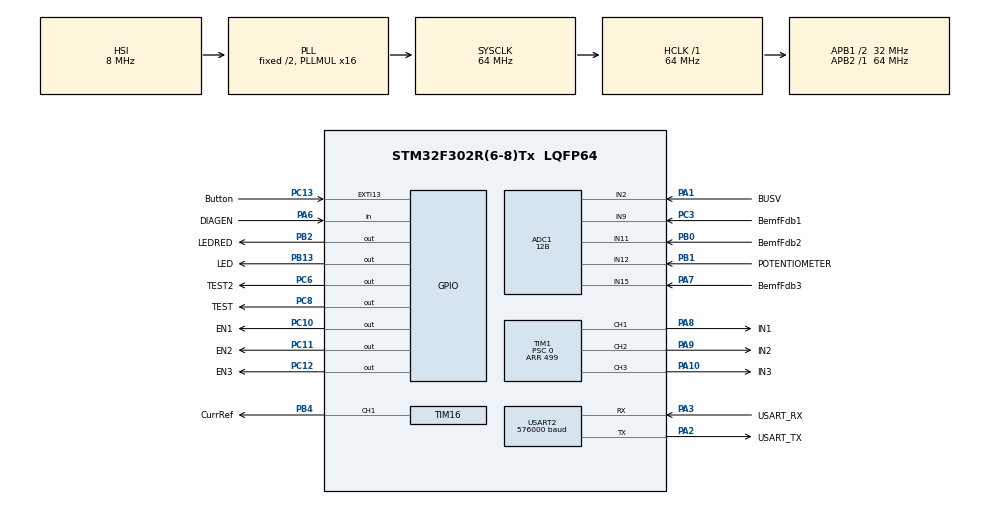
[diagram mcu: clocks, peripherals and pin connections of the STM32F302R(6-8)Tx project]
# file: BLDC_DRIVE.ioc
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ADC1.Channel-55\#ChannelRegularConversion=ADC_CHANNEL_12
ADC1.Channel-56\#ChannelRegularConversion=ADC_CHANNEL_9
ADC1.Channel-57\#ChannelRegularConversion=ADC_CHANNEL_11
ADC1.Channel-58\#ChannelRegularConversion=ADC_CHANNEL_9
ADC1.Channel-59\#ChannelRegularConversion=ADC_CHANNEL_9
ADC1.Channel-60\#ChannelRegularConversion=ADC_CHANNEL_2
ADC1.Channel-61\#ChannelRegularConversion=ADC_CHANNEL_2
ADC1.Channel-62\#ChannelRegularConversion=ADC_CHANNEL_2
ADC1.Channel-63\#ChannelRegularConversion=ADC_CHANNEL_2
ADC1.Channel-64\#ChannelRegularConversion=ADC_CHANNEL_2
ADC1.Channel-65\#ChannelRegularConversion=ADC_CHANNEL_2
ADC1.Channel-66\#ChannelRegularConversion=ADC_CHANNEL_9
ADC1.Channel-67\#ChannelRegularConversion=ADC_CHANNEL_11
ADC1.Channel-68\#ChannelRegularConversion=ADC_CHANNEL_15
ADC1.Channel-69\#ChannelRegularConversion=ADC_CHANNEL_9
ADC1.Channel-70\#ChannelRegularConversion=ADC_CHANNEL_11
ADC1.Channel-71\#ChannelRegularConversion=ADC_CHANNEL_15
ADC1.Channel-72\#ChannelRegularConversion=ADC_CHANNEL_9
ADC1.Channel-73\#ChannelRegularConversion=ADC_CHANNEL_11
ADC1.Channel-74\#ChannelRegularConversion=ADC_CHANNEL_15
ADC1.Channel-76\#ChannelRegularConversion=ADC_CHANNEL_12
ADC1.ClockPrescaler=ADC_CLOCK_SYNC_PCLK_DIV1
ADC1.ContinuousConvMode=DISABLE
ADC1.DMAContinuousRequests=ENABLE
ADC1.DataAlign=ADC_DATAALIGN_RIGHT
ADC1.DiscontinuousConvMode=DISABLE
ADC1.EOCSelection=ADC_EOC_SINGLE_CONV
ADC1.EnableAnalogWatchDog1=false
ADC1.EnableAnalogWatchDog2=false
ADC1.EnableAnalogWatchDog3=false
ADC1.EnableInjectedConversion=DISABLE
ADC1.EnableRegularConversion=ENABLE
ADC1.ExternalTrigConv=ADC_EXTERNALTRIGCONV_T1_TRGO
ADC1.ExternalTrigConvEdge=ADC_EXTERNALTRIGCONVEDGE_RISING
ADC1.LowPowerAutoWait=DISABLE
ADC1.NbrOfConversion=10
ADC1.NbrOfConversionFlag=1
ADC1.Offset-55\#ChannelRegularConversion=0
ADC1.Offset-56\#ChannelRegularConversion=0
ADC1.Offset-57\#ChannelRegularConversion=0
ADC1.Offset-58\#ChannelRegularConversion=0
ADC1.Offset-59\#ChannelRegularConversion=0
ADC1.Offset-60\#ChannelRegularConversion=0
ADC1.Offset-61\#ChannelRegularConversion=0
ADC1.Offset-62\#ChannelRegularConversion=0
ADC1.Offset-63\#ChannelRegularConversion=0
ADC1.Offset-64\#ChannelRegularConversion=0
ADC1.Offset-65\#ChannelRegularConversion=0
ADC1.Offset-66\#ChannelRegularConversion=0
ADC1.Offset-67\#ChannelRegularConversion=0
ADC1.Offset-68\#ChannelRegularConversion=0
ADC1.Offset-69\#ChannelRegularConversion=0
ADC1.Offset-70\#ChannelRegularConversion=0
ADC1.Offset-71\#ChannelRegularConversion=0
ADC1.Offset-72\#ChannelRegularConversion=0
ADC1.Offset-73\#ChannelRegularConversion=0
ADC1.Offset-74\#ChannelRegularConversion=0
ADC1.Offset-76\#ChannelRegularConversion=0
ADC1.OffsetNumber-55\#ChannelRegularConversion=ADC_OFFSET_NONE
ADC1.OffsetNumber-56\#ChannelRegularConversion=ADC_OFFSET_NONE
ADC1.OffsetNumber-57\#ChannelRegularConversion=ADC_OFFSET_NONE
ADC1.OffsetNumber-58\#ChannelRegularConversion=ADC_OFFSET_NONE
ADC1.OffsetNumber-59\#ChannelRegularConversion=ADC_OFFSET_NONE
ADC1.OffsetNumber-60\#ChannelRegularConversion=ADC_OFFSET_NONE
ADC1.OffsetNumber-61\#ChannelRegularConversion=ADC_OFFSET_NONE
ADC1.OffsetNumber-62\#ChannelRegularConversion=ADC_OFFSET_NONE
ADC1.OffsetNumber-63\#ChannelRegularConversion=ADC_OFFSET_NONE
ADC1.OffsetNumber-64\#ChannelRegularConversion=ADC_OFFSET_NONE
ADC1.OffsetNumber-65\#ChannelRegularConversion=ADC_OFFSET_NONE
ADC1.OffsetNumber-66\#ChannelRegularConversion=ADC_OFFSET_NONE
ADC1.OffsetNumber-67\#ChannelRegularConversion=ADC_OFFSET_NONE
ADC1.OffsetNumber-68\#ChannelRegularConversion=ADC_OFFSET_NONE
ADC1.OffsetNumber-69\#ChannelRegularConversion=ADC_OFFSET_NONE
ADC1.OffsetNumber-70\#ChannelRegularConversion=ADC_OFFSET_NONE
ADC1.OffsetNumber-71\#ChannelRegularConversion=ADC_OFFSET_NONE
ADC1.OffsetNumber-72\#ChannelRegularConversion=ADC_OFFSET_NONE
ADC1.OffsetNumber-73\#ChannelRegularConversion=ADC_OFFSET_NONE
ADC1.OffsetNumber-74\#ChannelRegularConversion=ADC_OFFSET_NONE
ADC1.OffsetNumber-76\#ChannelRegularConversion=ADC_OFFSET_NONE
ADC1.Overrun=ADC_OVR_DATA_OVERWRITTEN
ADC1.Rank-55\#ChannelRegularConversion=1
ADC1.Rank-56\#ChannelRegularConversion=2
ADC1.Rank-57\#ChannelRegularConversion=3
ADC1.Rank-58\#ChannelRegularConversion=4
ADC1.Rank-59\#ChannelRegularConversion=5
ADC1.Rank-60\#ChannelRegularConversion=6
ADC1.Rank-61\#ChannelRegularConversion=7
ADC1.Rank-62\#ChannelRegularConversion=8
ADC1.Rank-63\#ChannelRegularConversion=9
ADC1.Rank-64\#ChannelRegularConversion=10
ADC1.Rank-65\#ChannelRegularConversion=1
ADC1.Rank-66\#ChannelRegularConversion=1
ADC1.Rank-67\#ChannelRegularConversion=2
ADC1.Rank-68\#ChannelRegularConversion=3
ADC1.Rank-69\#ChannelRegularConversion=4
ADC1.Rank-70\#ChannelRegularConversion=5
ADC1.Rank-71\#ChannelRegularConversion=6
ADC1.Rank-72\#ChannelRegularConversion=7
ADC1.Rank-73\#ChannelRegularConversion=8
ADC1.Rank-74\#ChannelRegularConversion=9
ADC1.Rank-76\#ChannelRegularConversion=10
ADC1.Resolution=ADC_RESOLUTION_12B
ADC1.SamplingTime-55\#ChannelRegularConversion=ADC_SAMPLETIME_61CYCLES_5
ADC1.SamplingTime-56\#ChannelRegularConversion=ADC_SAMPLETIME_1CYCLE_5
ADC1.SamplingTime-57\#ChannelRegularConversion=ADC_SAMPLETIME_1CYCLE_5
ADC1.SamplingTime-58\#ChannelRegularConversion=ADC_SAMPLETIME_1CYCLE_5
ADC1.SamplingTime-59\#ChannelRegularConversion=ADC_SAMPLETIME_1CYCLE_5
ADC1.SamplingTime-60\#ChannelRegularConversion=ADC_SAMPLETIME_1CYCLE_5
ADC1.SamplingTime-61\#ChannelRegularConversion=ADC_SAMPLETIME_1CYCLE_5
ADC1.SamplingTime-62\#ChannelRegularConversion=ADC_SAMPLETIME_1CYCLE_5
ADC1.SamplingTime-63\#ChannelRegularConversion=ADC_SAMPLETIME_1CYCLE_5
ADC1.SamplingTime-64\#ChannelRegularConversion=ADC_SAMPLETIME_1CYCLE_5
ADC1.SamplingTime-65\#ChannelRegularConversion=ADC_SAMPLETIME_1CYCLE_5
ADC1.SamplingTime-66\#ChannelRegularConversion=ADC_SAMPLETIME_61CYCLES_5
ADC1.SamplingTime-67\#ChannelRegularConversion=ADC_SAMPLETIME_1CYCLE_5
ADC1.SamplingTime-68\#ChannelRegularConversion=ADC_SAMPLETIME_1CYCLE_5
ADC1.SamplingTime-69\#ChannelRegularConversion=ADC_SAMPLETIME_1CYCLE_5
ADC1.SamplingTime-70\#ChannelRegularConversion=ADC_SAMPLETIME_1CYCLE_5
ADC1.SamplingTime-71\#ChannelRegularConversion=ADC_SAMPLETIME_1CYCLE_5
ADC1.SamplingTime-72\#ChannelRegularConversion=ADC_SAMPLETIME_1CYCLE_5
ADC1.SamplingTime-73\#ChannelRegularConversion=ADC_SAMPLETIME_1CYCLE_5
ADC1.SamplingTime-74\#ChannelRegularConversion=ADC_SAMPLETIME_1CYCLE_5
ADC1.SamplingTime-76\#ChannelRegularConversion=ADC_SAMPLETIME_1CYCLE_5
ADC1.ScanConvMode=ADC_SCAN_ENABLE
ADC1.SubFamily=STM32F302x8
ADC1.master=1
Dma.ADC1.2.Direction=DMA_PERIPH_TO_MEMORY
Dma.ADC1.2.Instance=DMA1_Channel1
Dma.ADC1.2.MemDataAlignment=DMA_MDATAALIGN_HALFWORD
Dma.ADC1.2.MemInc=DMA_MINC_ENABLE
Dma.ADC1.2.Mode=DMA_CIRCULAR
Dma.ADC1.2.PeriphDataAlignment=DMA_PDATAALIGN_HALFWORD
Dma.ADC1.2.PeriphInc=DMA_PINC_DISABLE
Dma.ADC1.2.Priority=DMA_PRIORITY_LOW
Dma.Request0=USART2_TX
Dma.Request1=USART2_RX
Dma.Request2=ADC1
Dma.USART2_RX.1.Direction=DMA_PERIPH_TO_MEMORY
Dma.USART2_RX.1.Instance=DMA1_Channel6
Dma.USART2_RX.1.MemDataAlignment=DMA_MDATAALIGN_BYTE
Dma.USART2_RX.1.MemInc=DMA_MINC_ENABLE
Dma.USART2_RX.1.Mode=DMA_NORMAL
Dma.USART2_RX.1.PeriphDataAlignment=DMA_PDATAALIGN_BYTE
Dma.USART2_RX.1.PeriphInc=DMA_PINC_DISABLE
Dma.USART2_RX.1.Priority=DMA_PRIORITY_LOW
Dma.USART2_TX.0.Direction=DMA_MEMORY_TO_PERIPH
Dma.USART2_TX.0.Instance=DMA1_Channel7
Dma.USART2_TX.0.MemDataAlignment=DMA_MDATAALIGN_BYTE
Dma.USART2_TX.0.MemInc=DMA_MINC_ENABLE
Dma.USART2_TX.0.Mode=DMA_NORMAL
Dma.USART2_TX.0.PeriphDataAlignment=DMA_PDATAALIGN_BYTE
Dma.USART2_TX.0.PeriphInc=DMA_PINC_DISABLE
Dma.USART2_TX.0.Priority=DMA_PRIORITY_LOW
Mcu.Family=STM32F3
Mcu.Name=STM32F302R(6-8)Tx
Mcu.Package=LQFP64
NVIC.ADC1_IRQn=true\:0\:0\:false\:false\:true
NVIC.DMA1_Channel1_IRQn=true\:0\:0\:false\:false\:true
NVIC.DMA1_Channel6_IRQn=true\:0\:0\:false\:false\:true
NVIC.DMA1_Channel7_IRQn=true\:0\:0\:true\:false\:true
NVIC.EXTI15_10_IRQn=true\:0\:0\:false\:false\:true
NVIC.PriorityGroup=NVIC_PRIORITYGROUP_2
NVIC.TIM1_BRK_TIM15_IRQn=true\:0\:0\:false\:false\:true
NVIC.TIM2_IRQn=true\:1\:0\:true\:false\:true
NVIC.USART2_IRQn=true\:3\:0\:true\:false\:true
PA0.GPIO_Label=CurrFdbA
PA0.Signal=ADC1_IN1
PA1.GPIO_Label=BUSV
PA1.Mode=IN2-Single-Ended
PA1.Signal=ADC1_IN2
PA10.GPIO_Label=IN3
PA10.GPIO_Speed=GPIO_SPEED_FREQ_LOW
PA10.Signal=S_TIM1_CH3
PA12.Signal=S_TIM1_ETR
PA13.GPIO_Label=TMS
PA13.Signal=SYS_JTMS-SWDIO
PA14.GPIO_Label=TCK
PA14.Signal=SYS_JTCK-SWCLK
PA2.GPIO_Label=USART_TX
PA2.GPIO_Mode=GPIO_MODE_AF_PP
PA2.GPIO_PuPd=GPIO_NOPULL
PA2.GPIO_Speed=GPIO_SPEED_FREQ_LOW
PA2.Mode=Asynchronous
PA2.Signal=USART2_TX
PA3.GPIO_Label=USART_RX
PA3.GPIO_Mode=GPIO_MODE_AF_PP
PA3.GPIO_PuPd=GPIO_NOPULL
PA3.GPIO_Speed=GPIO_SPEED_FREQ_LOW
PA3.Mode=Asynchronous
PA3.Signal=USART2_RX
PA6.GPIO_Label=DIAGEN
PA6.Signal=GPIO_Input
PA7.GPIO_Label=BemfFdb3
PA7.Mode=IN15-Single-Ended
PA7.Signal=ADC1_IN15
PA8.GPIO_Label=IN1
PA8.GPIO_Speed=GPIO_SPEED_FREQ_LOW
PA8.Signal=S_TIM1_CH1
PA9.GPIO_Label=IN2
PA9.GPIO_Speed=GPIO_SPEED_FREQ_LOW
PA9.Signal=S_TIM1_CH2
PB0.GPIO_Label=BemfFdb2
PB0.Mode=IN11-Single-Ended
PB0.Signal=ADC1_IN11
PB1.GPIO_Label=POTENTIOMETER
PB1.Mode=IN12-Single-Ended
PB1.Signal=ADC1_IN12
PB13.GPIO_Label=LED
PB13.Signal=GPIO_Output
PB2.GPIO_Label=LEDRED
PB2.Signal=GPIO_Output
PB3.GPIO_Label=SWO
PB3.Signal=SYS_JTDO-TRACESWO
PB4.GPIO_Label=CurrRef
PB4.Signal=S_TIM16_CH1
PC0.GPIO_Label=CurrFdbC
PC0.Signal=ADCx_IN6
PC1.GPIO_Label=CurrFdbB
PC1.Signal=ADCx_IN7
PC10.GPIO_Label=EN1
PC10.Signal=GPIO_Output
PC11.GPIO_Label=EN2
PC11.Signal=GPIO_Output
PC12.GPIO_Label=EN3
PC12.Signal=GPIO_Output
PC13.GPIO_Label=Button
PC13.GPIO_ModeDefaultEXTI=GPIO_MODE_IT_FALLING
PC13.Signal=GPXTI13
PC14\ -\ OSC32_IN.Signal=RCC_OSC32_IN
PC15\ -\ OSC32_OUT.Signal=RCC_OSC32_OUT
PC3.GPIO_Label=BemfFdb1
PC3.Signal=ADCx_IN9
PC6.GPIO_Label=TEST2
PC6.Signal=GPIO_Output
PC8.GPIO_Label=TEST
PC8.GPIO_Speed=GPIO_SPEED_FREQ_MEDIUM
PC8.Signal=GPIO_Output
PF0-OSC_IN.Signal=RCC_OSC_IN
PF1-OSC_OUT.Signal=RCC_OSC_OUT
ProjectManager.HeapSize=0x200
ProjectManager.StackSize=0x400
ProjectManager.TargetToolchain=SW4STM32
RCC.AHBFreq_Value=64000000
RCC.APB1CLKDivider=RCC_HCLK_DIV2
RCC.APB1Freq_Value=32000000
RCC.APB1TimFreq_Value=64000000
RCC.APB2Freq_Value=64000000
RCC.APB2TimFreq_Value=64000000
RCC.CortexFreq_Value=64000000
RCC.HCLKFreq_Value=64000000
RCC.HSE_VALUE=8000000
RCC.HSI_VALUE=8000000
RCC.LSE_VALUE=32768
RCC.PLLM=8
RCC.PLLMUL=RCC_PLL_MUL16
RCC.PLLN=336
RCC.PLLP=RCC_PLLP_DIV4
RCC.PLLQ=7
RCC.RCC_PLLsource_Clock_Source_FROM_HSE=RCC_HSE_PREDIV_DIV2
RCC.SYSCLKFreq_VALUE=64000000
RCC.SYSCLKSourceVirtual=RCC_SYSCLKSOURCE_PLLCLK
RCC.USBFreq_Value=64000000
SH.ADCx_IN6.0=ADC1_IN6
SH.ADCx_IN7.0=ADC1_IN7
SH.ADCx_IN9.0=ADC1_IN9,IN9-Single-Ended
SH.S_TIM16_CH1.0=TIM16_CH1,PWM Generation1 CH1
SH.S_TIM1_CH1.0=TIM1_CH1,PWM Generation1 CH1
SH.S_TIM1_CH2.0=TIM1_CH2,PWM Generation2 CH2
SH.S_TIM1_CH3.0=TIM1_CH3,PWM Generation3 CH3
SH.S_TIM1_ETR.0=TIM1_ETR
TIM1.Channel-Output\ Compare4\ No\ Output=TIM_CHANNEL_4
TIM1.Channel-PWM\ Generation2\ CH2=TIM_CHANNEL_2
TIM1.Channel-PWM\ Generation3\ CH3=TIM_CHANNEL_3
TIM1.ClearChannel2=TIM_CHANNEL_2
TIM1.ClearChannel3=TIM_CHANNEL_3
TIM1.CounterMode=TIM_COUNTERMODE_CENTERALIGNED1
TIM1.OCMode_4=TIM_OCMODE_TOGGLE
TIM1.OCMode_PWM-PWM\ Generation1\ CH1=TIM_OCMODE_PWM1
TIM1.OCMode_PWM-PWM\ Generation3\ CH3=TIM_OCMODE_PWM1
TIM1.Period=499
TIM1.Prescaler=0
TIM1.Pulse-Output\ Compare4\ No\ Output=499
TIM1.Pulse-PWM\ Generation1\ CH1=0
TIM1.Pulse-PWM\ Generation2\ CH2=0
TIM1.Pulse-PWM\ Generation3\ CH3=0
TIM1.TIM_MasterOutputTrigger=TIM_TRGO_OC4REF
TIM15.Period=1129
TIM15.Prescaler=9999
TIM16.Period=999
TIM16.Pulse=499
TIM2.Period=1199
TIM2.Prescaler=640
USART2.BaudRate=576000
USART2.WordLength=UART_WORDLENGTH_8B
VP_TIM15_VS_ClockSourceINT.Mode=Internal
VP_TIM16_VS_ClockSourceINT.Mode=Enable_Timer
VP_TIM1_VS_ClockSourceINT.Mode=Internal
VP_TIM1_VS_no_output4.Mode=Output Compare4 No Output
VP_TIM2_VS_ClockSourceINT.Mode=Internal
board=NUCLEO-F302R8

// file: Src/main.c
/**
  ******************************************************************************
  * File Name          : main.c
  * Description        : Main program body
  ******************************************************************************
  *
  * COPYRIGHT(c) 2016 STMicroelectronics
  *
  * Redistribution and use in source and binary forms, with or without modification,
  * are permitted provided that the following conditions are met:
  *   1. Redistributions of source code must retain the above copyright notice,
  *      this list of conditions and the following disclaimer.
  *   2. Redistributions in binary form must reproduce the above copyright notice,
  *      this list of conditions and the following disclaimer in the documentation
  *      and/or other materials provided with the distribution.
  *   3. Neither the name of STMicroelectronics nor the names of its contributors
  *      may be used to endorse or promote products derived from this software
  *      without specific prior written permission.
  *
  * THIS SOFTWARE IS PROVIDED BY THE COPYRIGHT HOLDERS AND CONTRIBUTORS "AS IS"
  * AND ANY EXPRESS OR IMPLIED WARRANTIES, INCLUDING, BUT NOT LIMITED TO, THE
  * IMPLIED WARRANTIES OF MERCHANTABILITY AND FITNESS FOR A PARTICULAR PURPOSE ARE
  * DISCLAIMED. IN NO EVENT SHALL THE COPYRIGHT HOLDER OR CONTRIBUTORS BE LIABLE
  * FOR ANY DIRECT, INDIRECT, INCIDENTAL, SPECIAL, EXEMPLARY, OR CONSEQUENTIAL
  * DAMAGES (INCLUDING, BUT NOT LIMITED TO, PROCUREMENT OF SUBSTITUTE GOODS OR
  * SERVICES; LOSS OF USE, DATA, OR PROFITS; OR BUSINESS INTERRUPTION) HOWEVER
  * CAUSED AND ON ANY THEORY OF LIABILITY, WHETHER IN CONTRACT, STRICT LIABILITY,
  * OR TORT (INCLUDING NEGLIGENCE OR OTHERWISE) ARISING IN ANY WAY OUT OF THE USE
  * OF THIS SOFTWARE, EVEN IF ADVISED OF THE POSSIBILITY OF SUCH DAMAGE.
  *
  ******************************************************************************
  */
#include "main.h"
#include "stm32f3xx_hal.h"
#include "adc.h"
#include "dma.h"
#include "tim.h"
#include "usart.h"
#include "gpio.h"

/* USER CODE BEGIN Includes */
#include "comm.h"
#include "driver_bldc1.h"

/* USER CODE END Includes */

/* USER CODE BEGIN PV */
/* Private variables ---------------------------------------------------------*/
uint8_t buf[12];
/* USER CODE END PV */

void SystemClock_Config(void);
void Error_Handler(void);

/* USER CODE BEGIN PFP */
/* Private function prototypes -----------------------------------------------*/

/* USER CODE END PFP */

int main(void)
{

  /* MCU Configuration----------------------------------------------------------*/

  /* Reset of all peripherals, Initializes the Flash interface and the Systick. */
  HAL_Init();

  /* Configure the system clock */
  SystemClock_Config();

  /* Initialize all configured peripherals */
  MX_GPIO_Init();
  MX_DMA_Init();
  MX_USART2_UART_Init();
  MX_ADC1_Init();
  MX_TIM1_Init();
  MX_TIM2_Init();
  MX_TIM15_Init();
  MX_TIM16_Init();

  /* USER CODE BEGIN 2 */

	//inicjalizacja modułu komunikacyjnego
	commInit();

	//inicjalizacja modułu sterowLED_GPIO_Portania
	bldcInit();

	HAL_GPIO_WritePin(LED_GPIO_Port, LED_Pin, GPIO_PIN_SET);

  /* USER CODE END 2 */

  /* Infinite loop */
	while (1) {

  /* USER CODE BEGIN 3 */
		bldcLoop();
	}
  /* USER CODE END 3 */

}

/** System Clock Configuration
*/
void SystemClock_Config(void)
{

  RCC_OscInitTypeDef RCC_OscInitStruct;
  RCC_ClkInitTypeDef RCC_ClkInitStruct;
  RCC_PeriphCLKInitTypeDef PeriphClkInit;

    /**Initializes the CPU, AHB and APB busses clocks
    */
  RCC_OscInitStruct.OscillatorType = RCC_OSCILLATORTYPE_HSI;
  RCC_OscInitStruct.HSIState = RCC_HSI_ON;
  RCC_OscInitStruct.HSICalibrationValue = 16;
  RCC_OscInitStruct.PLL.PLLState = RCC_PLL_ON;
  RCC_OscInitStruct.PLL.PLLSource = RCC_PLLSOURCE_HSI;
  RCC_OscInitStruct.PLL.PLLMUL = RCC_PLL_MUL16;
  if (HAL_RCC_OscConfig(&RCC_OscInitStruct) != HAL_OK)
  {
    Error_Handler();
  }

    /**Initializes the CPU, AHB and APB busses clocks
    */
  RCC_ClkInitStruct.ClockType = RCC_CLOCKTYPE_HCLK|RCC_CLOCKTYPE_SYSCLK
                              |RCC_CLOCKTYPE_PCLK1|RCC_CLOCKTYPE_PCLK2;
  RCC_ClkInitStruct.SYSCLKSource = RCC_SYSCLKSOURCE_PLLCLK;
  RCC_ClkInitStruct.AHBCLKDivider = RCC_SYSCLK_DIV1;
  RCC_ClkInitStruct.APB1CLKDivider = RCC_HCLK_DIV2;
  RCC_ClkInitStruct.APB2CLKDivider = RCC_HCLK_DIV1;

  if (HAL_RCC_ClockConfig(&RCC_ClkInitStruct, FLASH_LATENCY_2) != HAL_OK)
  {
    Error_Handler();
  }

  PeriphClkInit.PeriphClockSelection = RCC_PERIPHCLK_TIM1|RCC_PERIPHCLK_TIM15
                              |RCC_PERIPHCLK_TIM16;
  PeriphClkInit.Tim1ClockSelection = RCC_TIM1CLK_HCLK;
  PeriphClkInit.Tim15ClockSelection = RCC_TIM15CLK_HCLK;
  PeriphClkInit.Tim16ClockSelection = RCC_TIM16CLK_HCLK;
  if (HAL_RCCEx_PeriphCLKConfig(&PeriphClkInit) != HAL_OK)
  {
    Error_Handler();
  }

    /**Configure the Systick interrupt time
    */
  HAL_SYSTICK_Config(HAL_RCC_GetHCLKFreq()/1000);

    /**Configure the Systick
    */
  HAL_SYSTICK_CLKSourceConfig(SYSTICK_CLKSOURCE_HCLK);

  /* SysTick_IRQn interrupt configuration */
  HAL_NVIC_SetPriority(SysTick_IRQn, 0, 0);
}

/* USER CODE BEGIN 4 */

void HAL_TIM_PeriodElapsedCallback(TIM_HandleTypeDef *htim) {

	//wywołanie drivera
	bldcIT(htim);

}

/**
 * @brief  Przerwanie systick
 * @param  None
 * @retval None
 */
void HAL_SYSTICK_Callback() {
	bldcSysTick();

}

/* USER CODE END 4 */

void Error_Handler(void)
{
	while (1) {
	}
}

/************************ (C) COPYRIGHT STMicroelectronics *****END OF FILE****/
